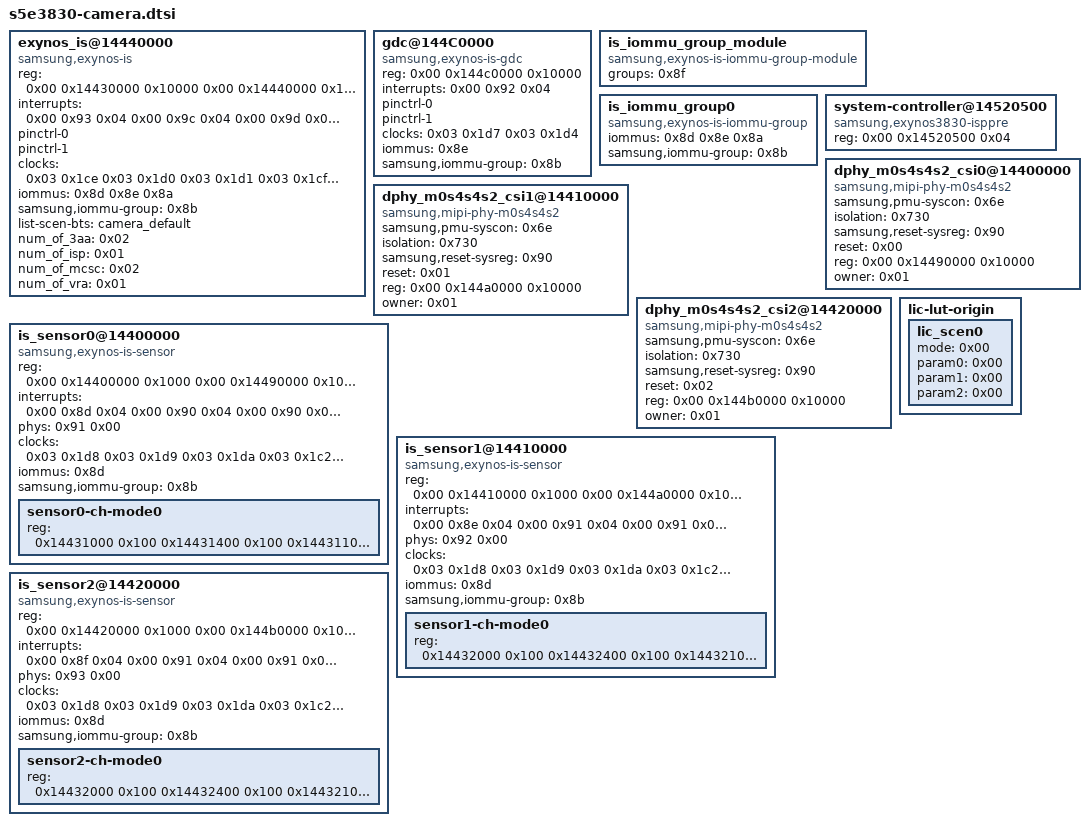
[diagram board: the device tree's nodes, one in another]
/* Samsung Exynos 850 (S5E3830) - image sensor pipeline and MIPI D-PHY */

	exynos_is@14440000 {
		compatible = "samsung,exynos-is";
		reg = <0x00 0x14430000 0x10000 0x00 0x14440000 0x10000 0x00 0x14440000 0x20000 0x00 0x14460000 0x10000 0x00 0x14470000 0x10000 0x00 0x14480000 0x10000 0x00 0x12ca0000 0x10000>;
		interrupts = <0x00 0x93 0x04 0x00 0x9c 0x04 0x00 0x9d 0x04 0x00 0x9e 0x04 0x00 0x9f 0x04 0x00 0xa0 0x04 0x00 0xa1 0x04 0x00 0xa8 0x04 0x00 0xab 0x04>;
		pinctrl-names = "default\0release";
		pinctrl-0;
		pinctrl-1;
		clocks = <0x03 0x1ce 0x03 0x1d0 0x03 0x1d1 0x03 0x1cf 0x03 0x204 0x03 0x1d1 0x03 0x1d2 0x03 0x1d3 0x03 0x1d4 0x03 0x1d5 0x03 0x1d6 0x03 0x1d7 0x03 0x1f6 0x03 0x1c2 0x03 0x1c3 0x03 0x1c4 0x03 0xc9 0x03 0xca 0x03 0xcb 0x03 0x1d8 0x03 0x1d9 0x03 0x1da>;
		clock-names = "IS_BUS\0IS_ITP\0IS_GDC\0IS_VRA\0MFCMSCL_MCSC\0UMUX_CLK_IS_BUS\0UMUX_CLK_IS_ITP\0UMUX_CLK_IS_VRA\0UMUX_CLK_IS_GDC\0GATE_CLK_ITP\0GATE_CLK_VRA\0GATE_CLK_GDC\0GATE_MCSC_QCH\0GATE_CSIS0_QCH\0GATE_CSIS1_QCH\0GATE_CSIS2_QCH\0GATE_DFTMUX_CMU_QCH_CLK_CIS0\0GATE_DFTMUX_CMU_QCH_CLK_CIS1\0GATE_DFTMUX_CMU_QCH_CLK_CIS2\0CIS_CLK0\0CIS_CLK1\0CIS_CLK2";
		status = "ok";
		iommus = <0x8d 0x8e 0x8a>;
		samsung,iommu-group = <0x8b>;
		#cooling-cells = <0x02>;
		list-scen-bts = "camera_default";
		num_of_3aa = <0x02>;
		num_of_isp = <0x01>;
		num_of_mcsc = <0x02>;
		num_of_vra = <0x01>;
		phandle = <0x149>;
	};

	gdc@144C0000 {
		compatible = "samsung,exynos-is-gdc";
		reg = <0x00 0x144c0000 0x10000>;
		interrupts = <0x00 0x92 0x04>;
		pinctrl-names = "default\0release";
		pinctrl-0;
		pinctrl-1;
		clocks = <0x03 0x1d7 0x03 0x1d4>;
		clock-names = "gate\0gate2";
		status = "okay";
		iommus = <0x8e>;
		samsung,iommu-group = <0x8b>;
		#cooling-cells = <0x02>;
		phandle = <0x14a>;
	};

	is_iommu_group_module {
		compatible = "samsung,exynos-is-iommu-group-module";
		groups = <0x8f>;
		phandle = <0x14b>;
	};

	is_iommu_group0 {
		compatible = "samsung,exynos-is-iommu-group";
		iommus = <0x8d 0x8e 0x8a>;
		samsung,iommu-group = <0x8b>;
		phandle = <0x8f>;
	};

	system-controller@14520500 {
		compatible = "samsung,exynos3830-isppre\0syscon";
		reg = <0x00 0x14520500 0x04>;
		phandle = <0x90>;
	};

	dphy_m0s4s4s2_csi0@14400000 {
		compatible = "samsung,mipi-phy-m0s4s4s2";
		samsung,pmu-syscon = <0x6e>;
		isolation = <0x730>;
		samsung,reset-sysreg = <0x90>;
		reset = <0x00>;
		reg = <0x00 0x14490000 0x10000>;
		owner = <0x01>;
		#phy-cells = <0x01>;
		phandle = <0x91>;
	};

	dphy_m0s4s4s2_csi1@14410000 {
		compatible = "samsung,mipi-phy-m0s4s4s2";
		samsung,pmu-syscon = <0x6e>;
		isolation = <0x730>;
		samsung,reset-sysreg = <0x90>;
		reset = <0x01>;
		reg = <0x00 0x144a0000 0x10000>;
		owner = <0x01>;
		#phy-cells = <0x01>;
		phandle = <0x92>;
	};

	dphy_m0s4s4s2_csi2@14420000 {
		compatible = "samsung,mipi-phy-m0s4s4s2";
		samsung,pmu-syscon = <0x6e>;
		isolation = <0x730>;
		samsung,reset-sysreg = <0x90>;
		reset = <0x02>;
		reg = <0x00 0x144b0000 0x10000>;
		owner = <0x01>;
		#phy-cells = <0x01>;
		phandle = <0x93>;
	};

	is_sensor0@14400000 {
		compatible = "samsung,exynos-is-sensor";
		#address-cells = <0x01>;
		#size-cells = <0x01>;
		reg = <0x00 0x14400000 0x1000 0x00 0x14490000 0x10000>;
		reg-names = "csi\0phy";
		interrupts = <0x00 0x8d 0x04 0x00 0x90 0x04 0x00 0x90 0x04 0x00 0x90 0x04 0x00 0x90 0x04>;
		interrupt-names = "csi\0mode0_VC0\0mode0_VC1\0mode0_VC2\0mode0_VC3";
		phys = <0x91 0x00>;
		phy-names = "csis_dphy";
		clocks = <0x03 0x1d8 0x03 0x1d9 0x03 0x1da 0x03 0x1c2 0x03 0x1c3 0x03 0x1c4>;
		clock-names = "CIS_CLK0\0CIS_CLK1\0CIS_CLK2\0GATE_CSIS0_QCH\0GATE_CSIS1_QCH\0GATE_CSIS2_QCH";
		iommus = <0x8d>;
		samsung,iommu-group = <0x8b>;
		phandle = <0x14c>;

		sensor0-ch-mode0 {
			reg = <0x14431000 0x100 0x14431400 0x100 0x14431100 0x100 0x14431400 0x100 0x14431200 0x100 0x14431400 0x100 0x14431300 0x100 0x14431400 0x100>;
			phandle = <0x14d>;
		};
	};

	is_sensor1@14410000 {
		compatible = "samsung,exynos-is-sensor";
		#address-cells = <0x01>;
		#size-cells = <0x01>;
		reg = <0x00 0x14410000 0x1000 0x00 0x144a0000 0x10000>;
		reg-names = "csi\0phy";
		interrupts = <0x00 0x8e 0x04 0x00 0x91 0x04 0x00 0x91 0x04 0x00 0x91 0x04 0x00 0x91 0x04>;
		interrupt-names = "csi\0mode0_VC0\0mode0_VC1\0mode0_VC2\0mode0_VC3";
		phys = <0x92 0x00>;
		phy-names = "csis_dphy";
		clocks = <0x03 0x1d8 0x03 0x1d9 0x03 0x1da 0x03 0x1c2 0x03 0x1c3 0x03 0x1c4>;
		clock-names = "CIS_CLK0\0CIS_CLK1\0CIS_CLK2\0GATE_CSIS0_QCH\0GATE_CSIS1_QCH\0GATE_CSIS2_QCH";
		iommus = <0x8d>;
		samsung,iommu-group = <0x8b>;
		phandle = <0x14e>;

		sensor1-ch-mode0 {
			reg = <0x14432000 0x100 0x14432400 0x100 0x14432100 0x100 0x14432400 0x100 0x14432200 0x100 0x14432400 0x100 0x14432300 0x100 0x14432400 0x100>;
			phandle = <0x14f>;
		};
	};

	is_sensor2@14420000 {
		compatible = "samsung,exynos-is-sensor";
		#address-cells = <0x01>;
		#size-cells = <0x01>;
		reg = <0x00 0x14420000 0x1000 0x00 0x144b0000 0x10000>;
		reg-names = "csi\0phy";
		interrupts = <0x00 0x8f 0x04 0x00 0x91 0x04 0x00 0x91 0x04 0x00 0x91 0x04 0x00 0x91 0x04>;
		interrupt-names = "csi\0mode0_VC0\0mode0_VC1\0mode0_VC2\0mode0_VC3";
		phys = <0x93 0x00>;
		phy-names = "csis_dphy";
		clocks = <0x03 0x1d8 0x03 0x1d9 0x03 0x1da 0x03 0x1c2 0x03 0x1c3 0x03 0x1c4>;
		clock-names = "CIS_CLK0\0CIS_CLK1\0CIS_CLK2\0GATE_CSIS0_QCH\0GATE_CSIS1_QCH\0GATE_CSIS2_QCH";
		iommus = <0x8d>;
		samsung,iommu-group = <0x8b>;
		phandle = <0x150>;

		sensor2-ch-mode0 {
			reg = <0x14432000 0x100 0x14432400 0x100 0x14432100 0x100 0x14432400 0x100 0x14432200 0x100 0x14432400 0x100 0x14432300 0x100 0x14432400 0x100>;
			phandle = <0x151>;
		};
	};

	lic-lut-origin {
		phandle = <0x152>;

		lic_scen0 {
			mode = <0x00>;
			param0 = <0x00>;
			param1 = <0x00>;
			param2 = <0x00>;
		};
	};
